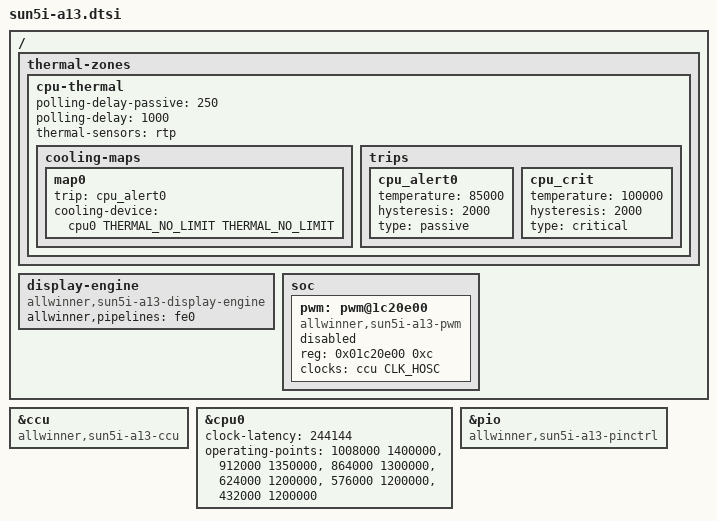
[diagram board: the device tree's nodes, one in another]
#include "sun5i.dtsi"
#include <dt-bindings/thermal/thermal.h>
/ {
	thermal-zones {
		cpu-thermal {
			polling-delay-passive = <250>;
			polling-delay = <1000>;
			thermal-sensors = <&rtp>;
			cooling-maps {
				map0 {
					trip = <&cpu_alert0>;
					cooling-device = <&cpu0 THERMAL_NO_LIMIT THERMAL_NO_LIMIT>;
				};
			};
			trips {
				cpu_alert0: cpu_alert0 {
					temperature = <85000>;
					hysteresis = <2000>;
					type = "passive";
				};
				cpu_crit: cpu_crit {
					temperature = <100000>;
					hysteresis = <2000>;
					type = "critical";
				};
			};
		};
	};
	display-engine {
		compatible = "allwinner,sun5i-a13-display-engine";
		allwinner,pipelines = <&fe0>;
	};
	soc {
		pwm: pwm@1c20e00 {
			compatible = "allwinner,sun5i-a13-pwm";
			reg = <0x01c20e00 0xc>;
			clocks = <&ccu CLK_HOSC>;
			#pwm-cells = <3>;
			status = "disabled";
		};
	};
};
&ccu {
	compatible = "allwinner,sun5i-a13-ccu";
};
&cpu0 {
	clock-latency = <244144>;  
	operating-points =
		<1008000 1400000>,
		<912000 1350000>,
		<864000 1300000>,
		<624000 1200000>,
		<576000 1200000>,
		<432000 1200000>;
	#cooling-cells = <2>;
};
&pio {
	compatible = "allwinner,sun5i-a13-pinctrl";
};
